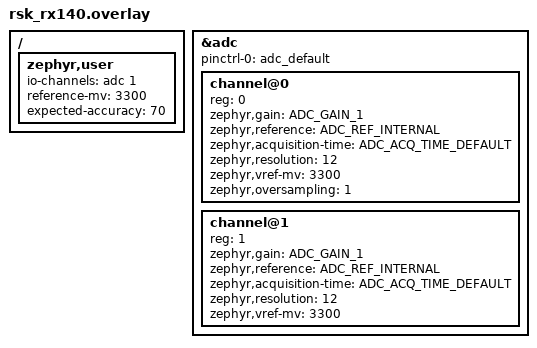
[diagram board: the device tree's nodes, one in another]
/*
 * Copyright (c) 2025 Renesas Electronics Corporation
 *
 * SPDX-License-Identifier: Apache-2.0
 */

/ {
	zephyr,user {
		io-channels = <&adc 1>;
		reference-mv = <3300>;
		expected-accuracy = <70>;
	};
};

&adc {
	pinctrl-0 = <&adc_default>;
	pinctrl-names = "default";
	#address-cells = <1>;
	#size-cells = <0>;
	status = "okay";

	channel@0 {
		reg = <0>;
		zephyr,gain = "ADC_GAIN_1";
		zephyr,reference = "ADC_REF_INTERNAL";
		zephyr,acquisition-time = <ADC_ACQ_TIME_DEFAULT>;
		zephyr,resolution = <12>;
		zephyr,vref-mv = <3300>;
		zephyr,oversampling = <1>;
	};

	channel@1 {
		reg = <1>;
		zephyr,gain = "ADC_GAIN_1";
		zephyr,reference = "ADC_REF_INTERNAL";
		zephyr,acquisition-time = <ADC_ACQ_TIME_DEFAULT>;
		zephyr,resolution = <12>;
		zephyr,vref-mv = <3300>;
	};
};
